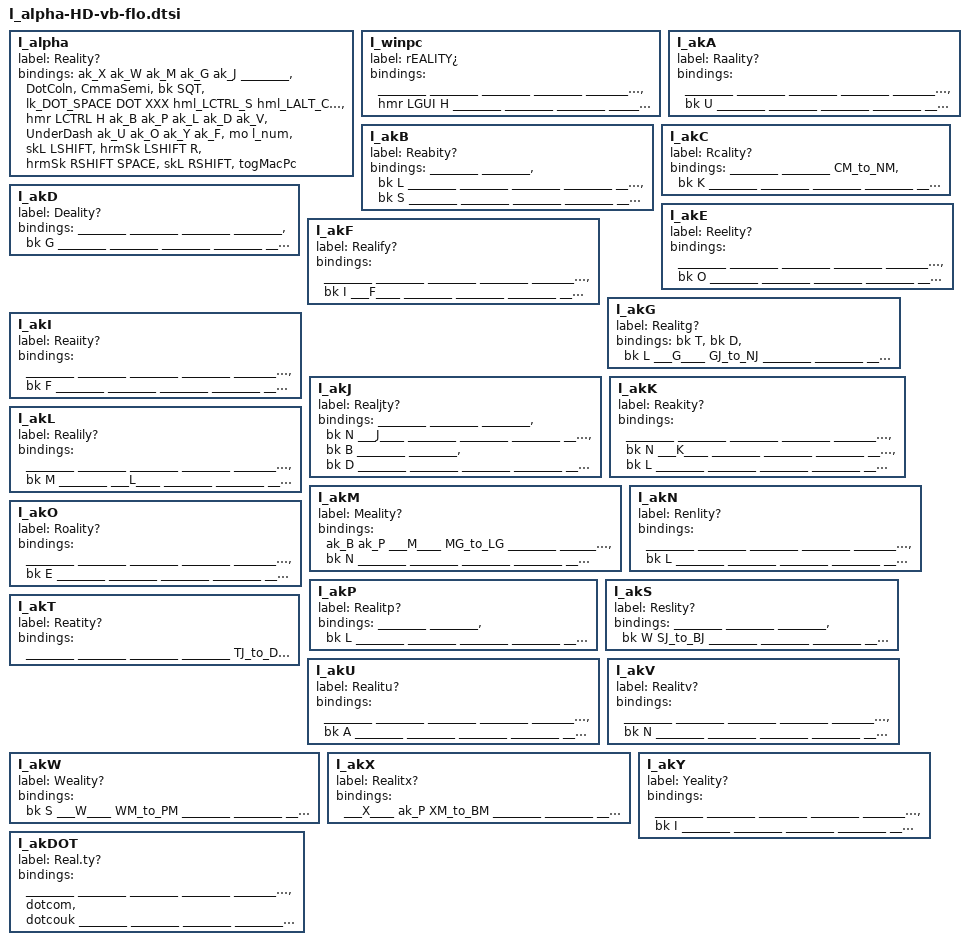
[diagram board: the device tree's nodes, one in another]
#define ________  &trans

// For these keys, I could use '________' (&trans) instead of the ak_X macros, but the ak_X macros make the ak key visible on the keymap-drawer, so I went with the ak_X macros.
#define ___A____ ak_A
#define ___B____ ak_B
#define ___C____ ak_C
#define ___D____ ak_D
#define ___E____ ak_E
#define ___F____ ak_F
#define ___G____ ak_G
#define ___H____ ak_H
#define ___I____ ak_I
#define ___J____ ak_J
#define ___K____ ak_K
#define ___L____ ak_L
#define ___M____ ak_M
#define ___N____ ak_N
#define ___O____ ak_O
#define ___P____ ak_P
#define ___Q____ ak_Q
#define ___R____ ak_R
#define ___S____ ak_S
#define ___T____ ak_T
#define ___U____ ak_U
#define ___V____ ak_V
#define ___W____ ak_W
#define ___X____ ak_X
#define ___Y____ ak_Y
#define ___Z____ ak_Z
#define _DOT____ ak_DOT


#define PB_to_SB    &replace_char_with_bigram_SB /* Symetry on BS(p) ✔ */
#define MG_to_LG    &replace_char_with_bigram_LG /* Symetry on GL(m) ✔ */
#define SJ_to_BJ    &replace_char_with_bigram_BJ /* Symetry on JB(s) ✔ <- Not really needed, but kept for consistency */
#define GJ_to_NJ    &replace_char_with_bigram_NJ /* Symetry on JN(g) ✔ <- Not really needed, but kept for consistency */
#define TJ_to_DJ    &replace_char_with_bigram_DJ /* Symetry on JD(t) ✔ <- Not really needed, but kept for consistency */
#define DK_to_LK    &replace_char_with_bigram_LK /* Symetry on KL(d) ✔ */
#define TK_to_NK    &replace_char_with_bigram_NK /* Symetry on KN(t) ✔ */
#define XM_to_BM    &replace_char_with_bigram_BM /* Symetry on MB(x) ✔ */
#define PN_to_LN    &replace_char_with_bigram_LN /* Symetry on NL(p) ✔ */
#define CM_to_NM    &replace_char_with_bigram_NM /* Symetry on MN(c) ✔ */
#define WM_to_PM    &replace_char_with_bigram_PM /* Symetry on MP(w) ✔ */
#define TV_to_NV    &replace_char_with_bigram_NV /* Symetry on VN(t) ✔ */



#define XXX 0
// Second param is ignored, so using XXX
#define hml_LCTRL_S  &hml_S LCTRL  XXX
#define hml_LALT_C   &hml_C LALT   XXX
#define hml_LGUI_N   &hml_N LGUI   XXX
#define hml_LSHIFT_T &hml_T LSHIFT XXX
#define hmr_LSHIFT_A &hmr_A LSHIFT XXX
#define hmr_LGUI_E   &hmr_E LGUI   XXX
#define hmr_LALT_I   &hmr_I LALT   XXX

#define hml_LGUI_S   &hml_S LGUI   XXX
#define hml_LCTRL_N  &hml_N LCTRL  XXX
#define hmr_LCTRL_E  &hmr_E LCTRL  XXX


/*
Removed from keymap (for now ?)

&SlshStar
&DqtRbk
&HashDllr

*/

                l_alpha {
                        label = "Reality?"; // The base layer ... ?
                        bindings = <

ak_X          ak_W         ak_M         ak_G            ak_J                          ________    &DotColn      &CmmaSemi   &bk SQT     &lk_DOT_SPACE DOT XXX

hml_LCTRL_S   hml_LALT_C   hml_LGUI_N   hml_LSHIFT_T    ak_K                          ________    hmr_LSHIFT_A  hmr_LGUI_E  hmr_LALT_I  &hmr LCTRL H

ak_B          ak_P         ak_L         ak_D            ak_V                          &UnderDash  ak_U          ak_O        ak_Y        ak_F

                     // &mo l_num   &bk LSHIFT          &hrmSk LSHIFT R        &hrmSk RSHIFT SPACE  &bskL RSHIFT  &togMacPc
                        &mo l_num   &skL LSHIFT          &hrmSk LSHIFT R        &hrmSk RSHIFT SPACE  &skL RSHIFT  &togMacPc
                     // &mo l_sym  &bsklt l_num LSHIFT  &blt l_nav R        &SpaceUnder       &mo l_fn     &togMacPc
                        >;
                };

                l_winpc {
                        label = "rEALITY¿"; // Windows layer, everything is upside down ⁉️
                        bindings = <
________      ________     ________     ________        ________                      ________    ________      ________    ________    ________
hml_LGUI_S    ________     hml_LCTRL_N  ________        ________                      ________    ________      hmr_LCTRL_E ________    &hmr LGUI H
________      ________     ________     ________        ________                      ________    ________      ________    ________    ________
                                        ________   ________   ________      ________   ________   ________
                        >;
                };

                l_akA {
                        label = "Raality?";
                        bindings = <
________   ________   ________   ________   ________          ________   ________   ________   ________   ________
________   ________   ________   ________   ________          ________   ___A____   ________   ________   &bk U
________   ________   ________   ________   ________          ________   ________   ________   ________   ________
                        ________   ________   ________      ________   ________   ________
                        >;
                };

                l_akB {
                        label = "Reabity?";
                        bindings = <
________   ________   &bk L      ________   ________          ________   ________   ________   ________   ________ /* 'L' is for the M->B->L sequence */
________   ________   ________   ________   ________          ________   ________   ________   ________   ________
___B____   &bk S      ________   ________   ________          ________   ________   ________   ________   ________
                        ________   ________   ________      ________   ________   ________
                        >;
                };

                l_akC {
                        label = "Rcality?";
                        bindings = <
________   ________   CM_to_NM   &bk K      ________          ________   ________   ________   ________   ________
________   ___C____   ________   ________   ________          ________   ________   ________   ________   ________
________   ________   ________   ________   ________          ________   ________   ________   ________   ________
                        ________   ________   ________      ________   ________   ________
                        >;
                };

                l_akD {
                        label = "Deality?";
                        bindings = <
________   ________   ________   ________   &bk G             ________   ________   ________   ________   ________
________   ________   ________   ________   DK_to_LK          ________   ________   ________   ________   ________
________   ________   ________   ___D____   ________          ________   ________   ________   ________   ________
                        ________   ________   ________      ________   ________   ________
                        >;
                };

                l_akE {
                        label = "Reelity?";
                        bindings = <
________   ________   ________   ________   ________          ________   ________   ________   ________   ________
________   ________   ________   ________   ________          ________   ________   ___E____   ________   &bk O
________   ________   ________   ________   ________          ________   ________   ________   ________   ________
                        ________   ________   ________      ________   ________   ________
                        >;
                };

                l_akF {
                        label = "Realify?";
                        bindings = <
________   ________   ________   ________   ________          ________   ________   ________   ________   ________
________   ________   ________   ________   ________          ________   ________   ________   ________   ________
________   ________   ________   ________   ________          ________   ________   ________   &bk I      ___F____
                        ________   ________   ________      ________   ________   ________
                        >;
                };

                l_akG {
                        label = "Realitg?";
                        bindings = <
&bk T      &bk D      &bk L      ___G____   GJ_to_NJ          ________   ________   ________   ________   ________
________   ________   ________   ________   ________          ________   ________   ________   ________   ________
________   ________   ________   ________   ________          ________   ________   ________   ________   ________
                        ________   ________   ________      ________   ________   ________
                        >;
                };

                l_akI {
                        label = "Reaiity?";
                        bindings = <
________   ________   ________   ________   ________          ________   ________   ________   ________   ________
________   ________   ________   ________   ________          ________   ________   ________   ___I____   &bk F
________   ________   ________   ________   ________          ________   ________   ________   ________   ________
                        ________   ________   ________      ________   ________   ________
                        >;
                };

                l_akJ {
                        label = "Realjty?";
                        bindings = <
/* NOTE
This AK layer is not really needed, but it is here for ensuring the symetry of the J key.
This makes the "replace_char_with_bigram_NJ/BJ" much more intuitive.
*/
________   ________   ________   &bk N      ___J____          ________   ________   ________   ________   ________
&bk B      ________   ________   &bk D      ________          ________   ________   ________   ________   ________
________   ________   ________   ________   ________          ________   ________   ________   ________   ________
                        ________   ________   ________      ________   ________   ________
                        >;
                };

                l_akK {
                        label = "Reakity?";
                        bindings = <
________   ________   ________   ________   ________          ________   ________   ________   ________   ________
________   ________   ________   &bk N      ___K____          ________   ________   ________   ________   ________
________   ________   ________   &bk L      ________          ________   ________   ________   ________   ________
                        ________   ________   ________      ________   ________   ________
                        >;
                };


                l_akL {
                        label = "Realily?";
                        bindings = <
________   ________   ________   ________   ________          ________   ________   ________   ________   ________
________   ________   ________   ________   ________          ________   ________   ________   ________   ________
&bk M      ________   ___L____   ________   ________          ________   ________   ________   ________   ________
                        ________   ________   ________      ________   ________   ________
                        >;
                };


                l_akM {
                        label = "Meality?";
                        bindings = <
ak_B       ak_P       ___M____   MG_to_LG   ________          ________   ________   ________   ________   ________
________   &bk N      ________   ________   ________          ________   ________   ________   ________   ________
________   ________   ________   ________   ________          ________   ________   ________   ________   ________
                        ________   ________   ________      ________   ________   ________
                        >;
                };

                l_akN {
                        label = "Renlity?";
                        bindings = <
________   ________   ________   ________   ________           ________   ________   ________   ________   ________
________   ________   ___N____   ________   ________           ________   ________   ________   ________   ________
________   &bk L      ________   ________   ________           ________   ________   ________   ________   ________
                        ________   ________   ________      ________   ________   ________
                        >;
                };

                l_akO {
                        label = "Roality?";
                        bindings = <
________   ________   ________   ________   ________          ________   ________   ________   ________   ________
________   ________   ________   ________   ________          ________   ________   ________   ________   &bk E
________   ________   ________   ________   ________          ________   ________   ___O____   ________   ________
                        ________   ________   ________      ________   ________   ________
                        >;
                };

                l_akP {
                        label = "Realitp?";
                        bindings = <
________   ________   &bk L      ________   ________          ________   ________   ________   ________   ________ /* 'L' is for the M->P->L and X->P->L sequences */
________   ________   PN_to_LN   ________   ________          ________   ________   ________   ________   ________
PB_to_SB   ___P____   ________   ________   ________          ________   ________   ________   ________   ________
                        ________   ________   ________      ________   ________   ________
                        >;
                };

                l_akS {
                        label = "Reslity?";
                        bindings = <
________   ________   ________   &bk W      SJ_to_BJ          ________   ________   ________   ________   ________
___S____   ________   ________   ________   ________          ________   ________   ________   ________   ________
________   ________   ________   ________   ________          ________   ________   ________   ________   ________
                        ________   ________   ________      ________   ________   ________
                        >;
                };

                l_akT {
                        label = "Reatity?";
                        bindings = <
________   ________   ________   ________   TJ_to_DJ          ________   ________   ________   ________   ________
________   ________   ________   ___T____   TK_to_NK          ________   ________   ________   ________   ________
________   ________   ________   ________   TV_to_NV          ________   ________   ________   ________   ________
                        ________   ________   ________      ________   ________   ________
                        >;
                };

                l_akU {
                        label = "Realitu?";
                        bindings = <
________   ________   ________   ________   ________          ________   ________   ________   ________   ________
________   ________   ________   ________   ________          ________   ________   ________   ________   &bk A
________   ________   ________   ________   ________          ________   ___U____   ________   ________   ________
                        ________   ________   ________      ________   ________   ________
                        >;
                };

                l_akV {
                        label = "Realitv?";
                        bindings = <
/* NOTE
This AK layer is not really needed, but it is here for ensuring the symetry of the V key.
This makes the "replace_char_with_bigram_NV" much more intuitive.
*/
________   ________   ________   ________   ________          ________   ________   ________   ________   ________
________   ________   ________   &bk N      ________          ________   ________   ________   ________   ________
________   ________   ________   ________   ___V____          ________   ________   ________   ________   ________
                        ________   ________   ________      ________   ________   ________
                        >;
                };


                l_akW {
                        label = "Weality?";
                        bindings = <
&bk S      ___W____   WM_to_PM   ________   ________          ________   ________   ________   ________   ________
________   ________   ________   ________   ________          ________   ________   ________   ________   ________
________   ________   ________   ________   ________          ________   ________   ________   ________   ________
                        ________   ________   ________      ________   ________   ________
                        >;
                };

                l_akX {
                        label = "Realitx?";
                        bindings = <
___X____   ak_P       XM_to_BM   ________   ________          ________   ________   ________   ________   ________
________   ________   ________   ________   ________          ________   ________   ________   ________   ________
________   ________   ________   ________   ________          ________   ________   ________   ________   ________
                        ________   ________   ________      ________   ________   ________
                        >;
                };

                l_akY {
                        label = "Yeality?";
                        bindings = <
________   ________   ________   ________   ________          ________   ________   ________   ________   ________
________   ________   ________   ________   ________          ________   ________   ________   ________   &bk I
________   ________   ________   ________   ________          ________   ________   ________   ___Y____   ________
                        ________   ________   ________      ________   ________   ________
                        >;
                };

// TODO: Fix 3 dots, include backspace before
#define _3_Dots_ &bk LA(SEMI)
                l_akDOT {
                        label = "Real.ty?";
                        bindings = <
________   ________   ________   ________   ________          ________   ________   _3_Dots_   &dotcom    &dotcouk
________   ________   ________   ________   ________          ________   ________   ________   ________   ________
________   ________   ________   ________   ________          ________   ________   ________   ________   ________
                        ________   ________   ________      ________   ________   ________
                        >;
                };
